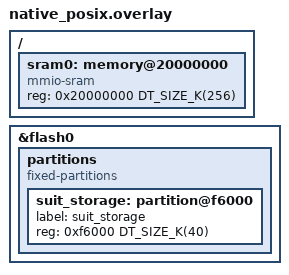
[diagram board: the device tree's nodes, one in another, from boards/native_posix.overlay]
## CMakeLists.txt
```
#
# Copyright (c) 2022 Nordic Semiconductor ASA
#
# SPDX-License-Identifier: LicenseRef-Nordic-5-Clause
#

cmake_minimum_required(VERSION 3.20.0)

find_package(Zephyr REQUIRED HINTS $ENV{ZEPHYR_BASE})

project(integration_test_fetch_integrated_payload_flash)
include(../cmake/test_template.cmake)

zephyr_library_link_libraries(suit_storage_interface)
zephyr_library_link_libraries(suit_execution_mode)
```

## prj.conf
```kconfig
#
# Copyright (c) 2022 Nordic Semiconductor ASA
#
# SPDX-License-Identifier: LicenseRef-Nordic-5-Clause
#

CONFIG_ZTEST=y

CONFIG_SUIT=y
CONFIG_SUIT_CRYPTO=y
CONFIG_PSA_WANT_ALG_ECDSA=y
CONFIG_SUIT_PROCESSOR=y
CONFIG_SUIT_PLATFORM=y
CONFIG_SUIT_LOG_LEVEL_DBG=y

CONFIG_SUIT_DEVCONFIG=y
CONFIG_SUIT_STORAGE=y
CONFIG_SUIT_MCI=y
CONFIG_SUIT_MCI_IMPL_CUSTOM=y
CONFIG_SUIT_METADATA=y
CONFIG_SUIT_PLAT_CHECK_COMPONENT_COMPATIBILITY=y
CONFIG_SUIT_PLAT_CHECK_CLASSES=y
CONFIG_SUIT_AUTHENTICATE=y

CONFIG_SUIT_DIGEST=y
CONFIG_SUIT_DIGEST_CACHE=y
CONFIG_SUIT_SINK_SELECTOR=y

CONFIG_SUIT_STREAM=y
CONFIG_SUIT_STREAM_SINK_DIGEST=y
CONFIG_SUIT_CHECK_IMAGE_MATCH=y

CONFIG_SUIT_STREAM_SINK_MEMPTR=y
CONFIG_SUIT_STREAM_SINK_FLASH=y
CONFIG_SUIT_STREAM_SOURCE_MEMPTR=y

CONFIG_SUIT_UTILS=y
CONFIG_SUIT_MEMPTR_STORAGE=y

CONFIG_ZCBOR=y
CONFIG_ZCBOR_CANONICAL=y

CONFIG_FLASH=y
CONFIG_FLASH_MAP=y

CONFIG_SUIT_EXECUTION_MODE=y
```

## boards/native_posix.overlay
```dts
/*
 * Copyright (c) 2023 Nordic Semiconductor ASA
 *
 * SPDX-License-Identifier: LicenseRef-Nordic-5-Clause
 */

&flash0 {
	partitions {
		compatible = "fixed-partitions";
		#address-cells = <1>;
		#size-cells = <1>;

		/* Use the last 40KB of NVM as suit storage. */
		suit_storage: partition@f6000 {
			label = "suit_storage";
			reg = <0xf6000 DT_SIZE_K(40)>;
		};
	};
};

/ {
	sram0: memory@20000000 {
		compatible = "mmio-sram";
		reg = <0x20000000 DT_SIZE_K(256)>;
	};
};
```

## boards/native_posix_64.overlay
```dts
/*
 * Copyright (c) 2023 Nordic Semiconductor ASA
 *
 * SPDX-License-Identifier: LicenseRef-Nordic-5-Clause
 */

&flash0 {
	partitions {
		compatible = "fixed-partitions";
		#address-cells = <1>;
		#size-cells = <1>;

		/* Use the last 44KB of NVM as suit storage. */
		suit_storage: partition@f5000 {
			reg = <0xf5000 DT_SIZE_K(44)>;
		};
	};
};

/ {
	sram0: memory@20000000 {
		compatible = "mmio-sram";
		reg = <0x20000000 DT_SIZE_K(256)>;
	};
};
```

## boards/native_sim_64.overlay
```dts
/*
 * Copyright (c) 2023 Nordic Semiconductor ASA
 *
 * SPDX-License-Identifier: LicenseRef-Nordic-5-Clause
 */

&flash0 {
	partitions {
		compatible = "fixed-partitions";
		#address-cells = <1>;
		#size-cells = <1>;

		/* Use the last 48KB of NVM as suit storage. */
		suit_storage: partition@f4000 {
			reg = <0xf4000 DT_SIZE_K(48)>;
		};
	};
};

/ {
	sram0: memory@20000000 {
		compatible = "mmio-sram";
		reg = <0x20000000 DT_SIZE_K(256)>;
	};
};
```

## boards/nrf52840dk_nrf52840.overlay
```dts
/*
 * Copyright (c) 2023 Nordic Semiconductor ASA
 *
 * SPDX-License-Identifier: LicenseRef-Nordic-5-Clause
 */

&flash0 {
	partitions {
		compatible = "fixed-partitions";
		#address-cells = <1>;
		#size-cells = <1>;

		/* Use the last 48KB of NVM as suit storage. */
		suit_storage: partition@f4000 {
			reg = <0xf4000 DT_SIZE_K(48)>;
		};
	};
};
```

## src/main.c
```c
/*
 * Copyright (c) 2022 Nordic Semiconductor ASA
 *
 * SPDX-License-Identifier: LicenseRef-Nordic-5-Clause
 */

#include <zephyr/ztest.h>
#include <stdint.h>

#include <suit.h>
#include <suit_platform.h>
#include <suit_storage.h>
#include <suit_mci.h>

#ifdef CONFIG_ARCH_POSIX
#include <zephyr/drivers/flash.h>
#define SOC_NV_FLASH_NODE	    DT_CHILD(DT_INST(0, zephyr_sim_flash), flash_0)
#define FLASH_SIMULATOR_BASE_OFFSET DT_REG_ADDR(SOC_NV_FLASH_NODE)
#define FLASH_SIMULATOR_FLASH_SIZE  DT_REG_SIZE(SOC_NV_FLASH_NODE)
#endif /* CONFIG_ARCH_POSIX */

/* The SUIT envelope is defined inside the board-specific manfest_*.c file. */
extern uint8_t manifest_buf[];
extern const size_t manifest_len;

static void *test_suit_setup(void)
{
	int err = suit_mci_init();

	zassert_equal(err, SUIT_PLAT_SUCCESS, "Unable to initialize MCI module");

#ifdef CONFIG_ARCH_POSIX
	static const struct device *const flash_dev =
		DEVICE_DT_GET(DT_CHOSEN(zephyr_flash_controller));

	err = flash_erase(flash_dev, FLASH_SIMULATOR_BASE_OFFSET, FLASH_SIMULATOR_FLASH_SIZE);
	zassert_equal(0, err, "Unable to erase flash area before test execution");
#endif /* CONFIG_ARCH_POSIX */

	return NULL;
}

ZTEST_SUITE(fetch_integrated_payload_flash_tests, NULL, test_suit_setup, NULL, NULL, NULL);

/** @brief Authenticate, validate and execute all command sequences from the sample SUIT envelope.
 *
 * @details The main purpose of this test is to give an entry point for SUIT processor platform
 * implementation. If the platform design requires it, please update the envelope payload, defined
 * at the beginning of this file.
 */
ZTEST(fetch_integrated_payload_flash_tests, test_suit_process)
{
	int err = SUIT_SUCCESS;

	err = suit_processor_init();
	zassert_equal(err, SUIT_SUCCESS, "Unable to initialise SUIT processor (err: %d)", err);

	err = suit_storage_init();
	zassert_equal(SUIT_PLAT_SUCCESS, err, "Failed to init suit storage (%d)", err);

	err = suit_process_sequence(manifest_buf, manifest_len, SUIT_SEQ_PARSE);
	zassert_equal(err, SUIT_SUCCESS, "Parsing SUIT envelope failed (err: %d)", err);

	for (enum suit_command_sequence i = SUIT_SEQ_PARSE + 1;
	     (i < SUIT_SEQ_MAX) && (err == SUIT_SUCCESS); i++) {
		err = suit_process_sequence(manifest_buf, manifest_len, i);
		if (err == SUIT_ERR_UNAVAILABLE_COMMAND_SEQ) {
			err = SUIT_SUCCESS;
		}
		zassert_equal(err, SUIT_SUCCESS, "Processing SUIT sequence %d failed with error %i",
			      i, err);
	}
}
```

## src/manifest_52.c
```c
/*
 * Copyright (c) 2022 Nordic Semiconductor ASA
 *
 * SPDX-License-Identifier: LicenseRef-Nordic-5-Clause
 */
#if defined(CONFIG_SOC_NRF52840) || defined(CONFIG_BOARD_NATIVE_SIM)
#include <suit_types.h>

/** @brief SUIT envelope generated using the manifest/manifest_52.yaml input file.
 *
 * @details This envelope contains 256-byte random numbers attached as an integrated
 *          payload and fetched directly into the memory-mapped region during install step.
 *          The envelope has been signed using the manifest/key_private.pem key.
 *
 * @note Please use the manifest_common/regenerate.sh script for regenerating payloads.
 */
uint8_t manifest_buf[] = {
	0xD8, 0x6B, 0xA4, 0x02, 0x58, 0x7A, 0x82, 0x58, 0x24, 0x82, 0x2F, 0x58, 0x20, 0x21, 0x79,
	0x6D, 0xE9, 0x61, 0x0F, 0x6F, 0xF9, 0xA6, 0xC7, 0x43, 0x69, 0x5F, 0xF1, 0x5A, 0x4B, 0x37,
	0x14, 0x3E, 0x7D, 0xD7, 0x2E, 0xBF, 0x8C, 0x34, 0x67, 0x33, 0xB8, 0x21, 0x72, 0xAF, 0x7E,
	0x58, 0x51, 0xD2, 0x84, 0x4A, 0xA2, 0x01, 0x26, 0x04, 0x45, 0x1A, 0x40, 0x00, 0x00, 0x00,
	0xA0, 0xF6, 0x58, 0x40, 0xD4, 0x80, 0xAE, 0xC9, 0x57, 0x17, 0x8D, 0xB0, 0x41, 0x36, 0xDF,
	0x95, 0x85, 0x8E, 0x40, 0x3D, 0xE1, 0xB5, 0x34, 0xEA, 0x14, 0xDA, 0xBB, 0xC4, 0x8E, 0x8D,
	0xED, 0x45, 0x08, 0xBD, 0x1A, 0xC4, 0x9E, 0xD6, 0x2C, 0xD1, 0x17, 0xFB, 0x81, 0x22, 0xBB,
	0xA2, 0xA5, 0xD2, 0xC7, 0x7A, 0x75, 0x8C, 0xA5, 0xE3, 0xA8, 0x59, 0x7D, 0x99, 0xA3, 0xF6,
	0xF1, 0x76, 0x8C, 0xAB, 0x6E, 0x23, 0xCF, 0x75, 0x03, 0x58, 0xFD, 0xA8, 0x01, 0x01, 0x02,
	0x01, 0x03, 0x58, 0x81, 0xA2, 0x02, 0x82, 0x84, 0x44, 0x63, 0x4D, 0x45, 0x4D, 0x41, 0x00,
	0x45, 0x1A, 0x00, 0x08, 0x00, 0x00, 0x43, 0x19, 0x10, 0x00, 0x82, 0x49, 0x68, 0x43, 0x41,
	0x4E, 0x44, 0x5F, 0x49, 0x4D, 0x47, 0x41, 0x00, 0x04, 0x58, 0x5C, 0x8C, 0x0C, 0x00, 0x14,
	0xA3, 0x01, 0x50, 0x76, 0x17, 0xDA, 0xA5, 0x71, 0xFD, 0x5A, 0x85, 0x8F, 0x94, 0xE2, 0x8D,
	0x73, 0x5C, 0xE9, 0xF4, 0x02, 0x50, 0x5B, 0x46, 0x9F, 0xD1, 0x90, 0xEE, 0x53, 0x9C, 0xA3,
	0x18, 0x68, 0x1B, 0x03, 0x69, 0x5E, 0x36, 0x0E, 0x19, 0x01, 0x00, 0x01, 0x0F, 0x02, 0x0F,
	0x0C, 0xF5, 0x14, 0xA1, 0x03, 0x58, 0x24, 0x82, 0x2F, 0x58, 0x20, 0x5F, 0xC3, 0x54, 0xBF,
	0x8E, 0x8C, 0x50, 0xFB, 0x4F, 0xBC, 0x2C, 0xFA, 0xEB, 0x04, 0x53, 0x41, 0xC9, 0x80, 0x6D,
	0xEA, 0xBD, 0xCB, 0x41, 0x54, 0xFB, 0x79, 0xCC, 0xA4, 0xF0, 0xC9, 0x8C, 0x12, 0x07, 0x45,
	0x84, 0x0C, 0x00, 0x03, 0x0F, 0x09, 0x45, 0x84, 0x0C, 0x00, 0x17, 0x02, 0x11, 0x58, 0x1E,
	0x90, 0x0C, 0x01, 0x14, 0xA1, 0x15, 0x69, 0x23, 0x66, 0x69, 0x6C, 0x65, 0x2E, 0x62, 0x69,
	0x6E, 0x15, 0x02, 0x03, 0x0F, 0x0C, 0x00, 0x14, 0xA1, 0x16, 0x01, 0x16, 0x02, 0x03, 0x0F,
	0x17, 0x82, 0x2F, 0x58, 0x20, 0xD0, 0x80, 0xD7, 0xEE, 0x16, 0x27, 0x88, 0xBD, 0xF7, 0x43,
	0x28, 0xC8, 0xC6, 0xD7, 0xA8, 0x86, 0xA4, 0xB4, 0x59, 0x83, 0x28, 0xFE, 0xA2, 0xD9, 0xAB,
	0xC3, 0x21, 0xDC, 0xB5, 0x5E, 0xC5, 0x1B, 0x05, 0x82, 0x4C, 0x6B, 0x49, 0x4E, 0x53, 0x54,
	0x4C, 0x44, 0x5F, 0x4D, 0x46, 0x53, 0x54, 0x50, 0x5B, 0x46, 0x9F, 0xD1, 0x90, 0xEE, 0x53,
	0x9C, 0xA3, 0x18, 0x68, 0x1B, 0x03, 0x69, 0x5E, 0x36, 0x17, 0x58, 0x86, 0xA1, 0x62, 0x65,
	0x6E, 0xA1, 0x84, 0x44, 0x63, 0x4D, 0x45, 0x4D, 0x41, 0x00, 0x45, 0x1A, 0x00, 0x08, 0x00,
	0x00, 0x43, 0x19, 0x10, 0x00, 0xA6, 0x01, 0x78, 0x18, 0x4E, 0x6F, 0x72, 0x64, 0x69, 0x63,
	0x20, 0x53, 0x65, 0x6D, 0x69, 0x63, 0x6F, 0x6E, 0x64, 0x75, 0x63, 0x74, 0x6F, 0x72, 0x20,
	0x41, 0x53, 0x41, 0x02, 0x64, 0x74, 0x65, 0x73, 0x74, 0x03, 0x6E, 0x6E, 0x6F, 0x72, 0x64,
	0x69, 0x63, 0x73, 0x65, 0x6D, 0x69, 0x2E, 0x63, 0x6F, 0x6D, 0x04, 0x74, 0x54, 0x68, 0x65,
	0x20, 0x74, 0x65, 0x73, 0x74, 0x20, 0x61, 0x70, 0x70, 0x6C, 0x69, 0x63, 0x61, 0x74, 0x69,
	0x6F, 0x6E, 0x05, 0x78, 0x1C, 0x53, 0x61, 0x6D, 0x70, 0x6C, 0x65, 0x20, 0x61, 0x70, 0x70,
	0x6C, 0x69, 0x63, 0x61, 0x74, 0x69, 0x6F, 0x6E, 0x20, 0x66, 0x6F, 0x72, 0x20, 0x74, 0x65,
	0x73, 0x74, 0x73, 0x06, 0x66, 0x76, 0x31, 0x2E, 0x30, 0x2E, 0x30, 0x69, 0x23, 0x66, 0x69,
	0x6C, 0x65, 0x2E, 0x62, 0x69, 0x6E, 0x59, 0x01, 0x00, 0xC7, 0x9C, 0xAB, 0x9D, 0xE8, 0x33,
	0x7F, 0x30, 0x14, 0xEB, 0xAC, 0x02, 0xAF, 0x26, 0x01, 0x5E, 0x80, 0x6D, 0x88, 0xA1, 0xDB,
	0x11, 0xA7, 0x31, 0xDF, 0xA6, 0xEC, 0xCB, 0x9B, 0x48, 0x0D, 0xC8, 0x34, 0x40, 0x6D, 0x30,
	0x86, 0x7D, 0xE8, 0x1B, 0xEC, 0x3C, 0xF5, 0x40, 0xD0, 0x48, 0x18, 0x82, 0x11, 0x9D, 0x7C,
	0x3F, 0x6C, 0xE5, 0x8F, 0xF1, 0xD3, 0x5D, 0xE1, 0x51, 0xF7, 0x6A, 0x0F, 0xAF, 0x0B, 0xBD,
	0x4C, 0x5F, 0xA5, 0x34, 0x1A, 0x66, 0xDB, 0x22, 0xEC, 0x63, 0xED, 0x4B, 0xAB, 0xC7, 0xC8,
	0xF7, 0x59, 0xD8, 0xD6, 0x9E, 0xEC, 0x71, 0x1B, 0x24, 0x20, 0xB9, 0xAE, 0xE1, 0x3B, 0xFC,
	0xAE, 0xB8, 0x77, 0xAC, 0xA4, 0x57, 0x34, 0x97, 0x84, 0x4F, 0x58, 0xD5, 0x68, 0x08, 0x6F,
	0xE3, 0x9C, 0x7E, 0x1B, 0xD7, 0x38, 0x22, 0x98, 0x48, 0xF8, 0x7A, 0x67, 0xB2, 0xD9, 0xAC,
	0xC5, 0x34, 0xC1, 0x27, 0x82, 0x8E, 0x42, 0x79, 0x84, 0x21, 0x37, 0x4C, 0x41, 0x4A, 0x0F,
	0xE2, 0x7F, 0xA0, 0x6A, 0x19, 0x13, 0x3D, 0x52, 0x22, 0x7F, 0xD6, 0x2F, 0x71, 0x12, 0x76,
	0xAB, 0x25, 0x9C, 0xFC, 0x67, 0x08, 0x03, 0x7C, 0xDB, 0x18, 0xE6, 0x45, 0xF8, 0x99, 0xC2,
	0x9E, 0x2C, 0xE3, 0x9B, 0x25, 0xA9, 0x7B, 0x09, 0xFF, 0x00, 0x57, 0x26, 0x08, 0x0A, 0x11,
	0x42, 0xCF, 0x82, 0xA2, 0x6B, 0x2A, 0x99, 0xF9, 0x71, 0x9D, 0x14, 0x19, 0x5C, 0x5C, 0x78,
	0x31, 0x60, 0x42, 0x4A, 0x18, 0x1F, 0xEC, 0x78, 0x6A, 0x9A, 0x7C, 0x4F, 0xCF, 0xE8, 0x5A,
	0x29, 0x65, 0xCD, 0x01, 0x3B, 0x6D, 0x53, 0xBB, 0xC6, 0xDB, 0xDA, 0xD5, 0x8F, 0xF7, 0xF4,
	0xD9, 0xB9, 0x0A, 0x03, 0x4B, 0xFF, 0x33, 0xAB, 0x3B, 0xC5, 0xAF, 0xD0, 0xB8, 0x2C, 0x0F,
	0x6A, 0xA9, 0x11, 0xB0, 0xE8, 0x57, 0x8C, 0x92, 0x53, 0x81};

const size_t manifest_len = sizeof(manifest_buf);
#endif /* CONFIG_SOC_NRF52840 || CONFIG_BOARD_NATIVE_SIM */
```

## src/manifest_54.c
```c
/*
 * Copyright (c) 2022 Nordic Semiconductor ASA
 *
 * SPDX-License-Identifier: LicenseRef-Nordic-5-Clause
 */
#if defined(CONFIG_SOC_SERIES_NRF54HX)
#include <suit_types.h>

/** @brief SUIT envelope generated using the manifest/manifest_54.yaml input file.
 *
 * @details This envelope contains 256-byte random numbers attached as an integrated
 *          payload and fetched directly into the memory-mapped region during install step.
 *          The envelope has been signed using the manifest/key_private.pem key.
 *
 * @note Please use the manifest_common/regenerate.sh script for regenerating payloads.
 */
uint8_t manifest_buf[] = {
	0xD8, 0x6B, 0xA4, 0x02, 0x58, 0x7A, 0x82, 0x58, 0x24, 0x82, 0x2F, 0x58, 0x20, 0x6D, 0xD8,
	0xC6, 0xEB, 0x81, 0xF3, 0x8D, 0x83, 0x7C, 0x25, 0x9F, 0xA8, 0xF9, 0xA8, 0x4E, 0x63, 0x4A,
	0xAB, 0x0D, 0x71, 0xAE, 0x01, 0xF1, 0x71, 0xB4, 0xD4, 0x46, 0x70, 0x03, 0x30, 0xA3, 0xF2,
	0x58, 0x51, 0xD2, 0x84, 0x4A, 0xA2, 0x01, 0x26, 0x04, 0x45, 0x1A, 0x40, 0x00, 0x00, 0x00,
	0xA0, 0xF6, 0x58, 0x40, 0x35, 0xD5, 0xC3, 0x2C, 0x0E, 0x05, 0x4F, 0x64, 0x34, 0x84, 0x67,
	0x1E, 0xB4, 0x8E, 0x93, 0x0B, 0x3A, 0x7C, 0xB4, 0xE9, 0x9A, 0x7F, 0x1D, 0x9A, 0xAB, 0xFE,
	0x03, 0xEC, 0x96, 0xEA, 0x1F, 0x91, 0xDB, 0xCE, 0xAD, 0x32, 0x15, 0x40, 0x32, 0xFB, 0x6B,
	0x8E, 0x58, 0xC5, 0xB1, 0x2E, 0x7A, 0x95, 0x0B, 0xD5, 0xC5, 0x04, 0xA8, 0xE9, 0x3E, 0x80,
	0x00, 0x7D, 0x74, 0x01, 0x4F, 0x09, 0x23, 0x57, 0x03, 0x58, 0xFF, 0xA8, 0x01, 0x01, 0x02,
	0x01, 0x03, 0x58, 0x83, 0xA2, 0x02, 0x82, 0x84, 0x44, 0x63, 0x4D, 0x45, 0x4D, 0x41, 0x00,
	0x45, 0x1A, 0x0E, 0x0A, 0xA0, 0x00, 0x45, 0x1A, 0x00, 0x07, 0xF8, 0x00, 0x82, 0x49, 0x68,
	0x43, 0x41, 0x4E, 0x44, 0x5F, 0x49, 0x4D, 0x47, 0x41, 0x00, 0x04, 0x58, 0x5C, 0x8C, 0x0C,
	0x00, 0x14, 0xA3, 0x01, 0x50, 0x76, 0x17, 0xDA, 0xA5, 0x71, 0xFD, 0x5A, 0x85, 0x8F, 0x94,
	0xE2, 0x8D, 0x73, 0x5C, 0xE9, 0xF4, 0x02, 0x50, 0x5B, 0x46, 0x9F, 0xD1, 0x90, 0xEE, 0x53,
	0x9C, 0xA3, 0x18, 0x68, 0x1B, 0x03, 0x69, 0x5E, 0x36, 0x0E, 0x19, 0x01, 0x00, 0x01, 0x0F,
	0x02, 0x0F, 0x0C, 0xF5, 0x14, 0xA1, 0x03, 0x58, 0x24, 0x82, 0x2F, 0x58, 0x20, 0x5F, 0xC3,
	0x54, 0xBF, 0x8E, 0x8C, 0x50, 0xFB, 0x4F, 0xBC, 0x2C, 0xFA, 0xEB, 0x04, 0x53, 0x41, 0xC9,
	0x80, 0x6D, 0xEA, 0xBD, 0xCB, 0x41, 0x54, 0xFB, 0x79, 0xCC, 0xA4, 0xF0, 0xC9, 0x8C, 0x12,
	0x07, 0x45, 0x84, 0x0C, 0x00, 0x03, 0x0F, 0x09, 0x45, 0x84, 0x0C, 0x00, 0x17, 0x02, 0x11,
	0x58, 0x1E, 0x90, 0x0C, 0x01, 0x14, 0xA1, 0x15, 0x69, 0x23, 0x66, 0x69, 0x6C, 0x65, 0x2E,
	0x62, 0x69, 0x6E, 0x15, 0x02, 0x03, 0x0F, 0x0C, 0x00, 0x14, 0xA1, 0x16, 0x01, 0x16, 0x02,
	0x03, 0x0F, 0x17, 0x82, 0x2F, 0x58, 0x20, 0x37, 0xD1, 0xAD, 0xE5, 0x6F, 0xDF, 0xE8, 0xA1,
	0xDC, 0x0A, 0x40, 0xB4, 0x16, 0xE7, 0xD7, 0xE1, 0xE0, 0xA1, 0x85, 0xB7, 0x10, 0x73, 0xA4,
	0xC2, 0x89, 0xC3, 0x81, 0x07, 0x28, 0xBB, 0x4F, 0x57, 0x05, 0x82, 0x4C, 0x6B, 0x49, 0x4E,
	0x53, 0x54, 0x4C, 0x44, 0x5F, 0x4D, 0x46, 0x53, 0x54, 0x50, 0x5B, 0x46, 0x9F, 0xD1, 0x90,
	0xEE, 0x53, 0x9C, 0xA3, 0x18, 0x68, 0x1B, 0x03, 0x69, 0x5E, 0x36, 0x17, 0x58, 0x88, 0xA1,
	0x62, 0x65, 0x6E, 0xA1, 0x84, 0x44, 0x63, 0x4D, 0x45, 0x4D, 0x41, 0x00, 0x45, 0x1A, 0x0E,
	0x0A, 0xA0, 0x00, 0x45, 0x1A, 0x00, 0x07, 0xF8, 0x00, 0xA6, 0x01, 0x78, 0x18, 0x4E, 0x6F,
	0x72, 0x64, 0x69, 0x63, 0x20, 0x53, 0x65, 0x6D, 0x69, 0x63, 0x6F, 0x6E, 0x64, 0x75, 0x63,
	0x74, 0x6F, 0x72, 0x20, 0x41, 0x53, 0x41, 0x02, 0x64, 0x74, 0x65, 0x73, 0x74, 0x03, 0x6E,
	0x6E, 0x6F, 0x72, 0x64, 0x69, 0x63, 0x73, 0x65, 0x6D, 0x69, 0x2E, 0x63, 0x6F, 0x6D, 0x04,
	0x74, 0x54, 0x68, 0x65, 0x20, 0x74, 0x65, 0x73, 0x74, 0x20, 0x61, 0x70, 0x70, 0x6C, 0x69,
	0x63, 0x61, 0x74, 0x69, 0x6F, 0x6E, 0x05, 0x78, 0x1C, 0x53, 0x61, 0x6D, 0x70, 0x6C, 0x65,
	0x20, 0x61, 0x70, 0x70, 0x6C, 0x69, 0x63, 0x61, 0x74, 0x69, 0x6F, 0x6E, 0x20, 0x66, 0x6F,
	0x72, 0x20, 0x74, 0x65, 0x73, 0x74, 0x73, 0x06, 0x66, 0x76, 0x31, 0x2E, 0x30, 0x2E, 0x30,
	0x69, 0x23, 0x66, 0x69, 0x6C, 0x65, 0x2E, 0x62, 0x69, 0x6E, 0x59, 0x01, 0x00, 0xC7, 0x9C,
	0xAB, 0x9D, 0xE8, 0x33, 0x7F, 0x30, 0x14, 0xEB, 0xAC, 0x02, 0xAF, 0x26, 0x01, 0x5E, 0x80,
	0x6D, 0x88, 0xA1, 0xDB, 0x11, 0xA7, 0x31, 0xDF, 0xA6, 0xEC, 0xCB, 0x9B, 0x48, 0x0D, 0xC8,
	0x34, 0x40, 0x6D, 0x30, 0x86, 0x7D, 0xE8, 0x1B, 0xEC, 0x3C, 0xF5, 0x40, 0xD0, 0x48, 0x18,
	0x82, 0x11, 0x9D, 0x7C, 0x3F, 0x6C, 0xE5, 0x8F, 0xF1, 0xD3, 0x5D, 0xE1, 0x51, 0xF7, 0x6A,
	0x0F, 0xAF, 0x0B, 0xBD, 0x4C, 0x5F, 0xA5, 0x34, 0x1A, 0x66, 0xDB, 0x22, 0xEC, 0x63, 0xED,
	0x4B, 0xAB, 0xC7, 0xC8, 0xF7, 0x59, 0xD8, 0xD6, 0x9E, 0xEC, 0x71, 0x1B, 0x24, 0x20, 0xB9,
	0xAE, 0xE1, 0x3B, 0xFC, 0xAE, 0xB8, 0x77, 0xAC, 0xA4, 0x57, 0x34, 0x97, 0x84, 0x4F, 0x58,
	0xD5, 0x68, 0x08, 0x6F, 0xE3, 0x9C, 0x7E, 0x1B, 0xD7, 0x38, 0x22, 0x98, 0x48, 0xF8, 0x7A,
	0x67, 0xB2, 0xD9, 0xAC, 0xC5, 0x34, 0xC1, 0x27, 0x82, 0x8E, 0x42, 0x79, 0x84, 0x21, 0x37,
	0x4C, 0x41, 0x4A, 0x0F, 0xE2, 0x7F, 0xA0, 0x6A, 0x19, 0x13, 0x3D, 0x52, 0x22, 0x7F, 0xD6,
	0x2F, 0x71, 0x12, 0x76, 0xAB, 0x25, 0x9C, 0xFC, 0x67, 0x08, 0x03, 0x7C, 0xDB, 0x18, 0xE6,
	0x45, 0xF8, 0x99, 0xC2, 0x9E, 0x2C, 0xE3, 0x9B, 0x25, 0xA9, 0x7B, 0x09, 0xFF, 0x00, 0x57,
	0x26, 0x08, 0x0A, 0x11, 0x42, 0xCF, 0x82, 0xA2, 0x6B, 0x2A, 0x99, 0xF9, 0x71, 0x9D, 0x14,
	0x19, 0x5C, 0x5C, 0x78, 0x31, 0x60, 0x42, 0x4A, 0x18, 0x1F, 0xEC, 0x78, 0x6A, 0x9A, 0x7C,
	0x4F, 0xCF, 0xE8, 0x5A, 0x29, 0x65, 0xCD, 0x01, 0x3B, 0x6D, 0x53, 0xBB, 0xC6, 0xDB, 0xDA,
	0xD5, 0x8F, 0xF7, 0xF4, 0xD9, 0xB9, 0x0A, 0x03, 0x4B, 0xFF, 0x33, 0xAB, 0x3B, 0xC5, 0xAF,
	0xD0, 0xB8, 0x2C, 0x0F, 0x6A, 0xA9, 0x11, 0xB0, 0xE8, 0x57, 0x8C, 0x92, 0x53, 0x81};

const size_t manifest_len = sizeof(manifest_buf);
#endif /* CONFIG_SOC_SERIES_NRF54HX */
```
